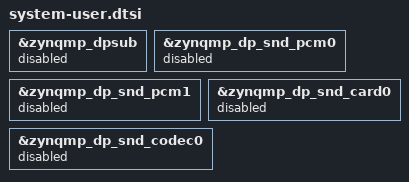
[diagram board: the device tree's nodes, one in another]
/include/ "system-conf.dtsi"
/ {
};

&zynqmp_dpsub {
	status = "disabled";
};

&zynqmp_dp_snd_pcm0 {
	status = "disabled";
};

&zynqmp_dp_snd_pcm1 {
	status = "disabled";
};

&zynqmp_dp_snd_card0 {
	status = "disabled";
};

&zynqmp_dp_snd_codec0 {
	status = "disabled";
};
